# RP2040 register map
Vendor: Raspberry Pi; File version: 2025.06.15
CPU: CM0PLUS r0p1, little endian, 2 interrupt priority bits
Registers are 32-bit, read-write, no defined reset value unless marked. A register's access mark holds for its fields unless they carry their own. Offsets are from the block's base; [hi:lo] are bit positions; {n}, {i} and the like mark numbered series; 'fields as' and 'values as' point back to an identical list.

## CLOCKS
Base 0x40008000
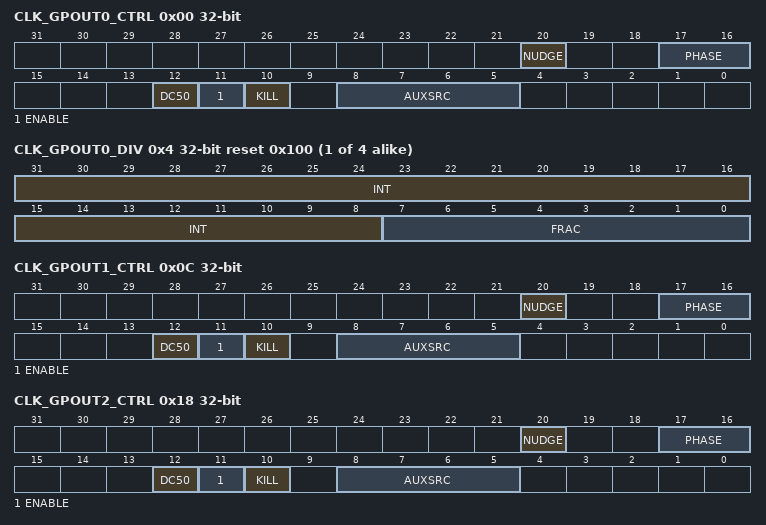
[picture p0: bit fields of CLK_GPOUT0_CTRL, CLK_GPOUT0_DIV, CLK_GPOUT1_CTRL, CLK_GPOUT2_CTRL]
0x00 CLK_GPOUT0_CTRL — Clock control, can be changed on-the-fly (except for auxsrc)
  [20] NUDGE — An edge on this signal shifts the phase of the output by 1 cycle of the input clock This can be done at any time
  [17:16] PHASE — This delays the enable signal by up to 3 cycles of the input clock This must be set before the clock is enabled to have any effect
  [12] DC50 — Enables duty cycle correction for odd divisors
  [11] ENABLE — Starts and stops the clock generator cleanly
  [10] KILL — Asynchronously kills the clock generator
  [8:5] AUXSRC — Selects the auxiliary clock source, will glitch when switching
    0=clksrc_pll_sys (None); 1=clksrc_gpin0 (None); 10=clk_ref (None); 2=clksrc_gpin1 (None); 3=clksrc_pll_usb (None); 4=rosc_clksrc (None); 5=xosc_clksrc (None); 6=clk_sys (None); 7=clk_usb (None); 8=clk_adc (None); 9=clk_rtc (None)
{0x4+0xC*i} CLK_GPOUT{i}_DIV reset 0x100 (reset mask 0x0) (i=0..3) — Clock divisor, can be changed on-the-fly
  [31:8] INT — Integer component of the divisor, 0 -> divide by 2^16
  [7:0] FRAC — Fractional component of the divisor
{0x8+0xC*i} CLK_GPOUT{i}_SELECTED ro reset 0x1 (reset mask 0x0) (i=0..3) — Indicates which SRC is currently selected by the glitchless mux (one-hot). This slice does not have a glitchless mux (only the AUX_SRC field is present, not SRC) so this register is hardwired to 0x1.
0x0C CLK_GPOUT1_CTRL — Clock control, can be changed on-the-fly (except for auxsrc)
  fields as CLK_GPOUT0_CTRL
0x18 CLK_GPOUT2_CTRL — Clock control, can be changed on-the-fly (except for auxsrc)
  [20] NUDGE — An edge on this signal shifts the phase of the output by 1 cycle of the input clock This can be done at any time
  [17:16] PHASE — This delays the enable signal by up to 3 cycles of the input clock This must be set before the clock is enabled to have any effect
  [12] DC50 — Enables duty cycle correction for odd divisors
  [11] ENABLE — Starts and stops the clock generator cleanly
  [10] KILL — Asynchronously kills the clock generator
  [8:5] AUXSRC — Selects the auxiliary clock source, will glitch when switching
    0=clksrc_pll_sys (None); 1=clksrc_gpin0 (None); 10=clk_ref (None); 2=clksrc_gpin1 (None); 3=clksrc_pll_usb (None); 4=rosc_clksrc_ph (None); 5=xosc_clksrc (None); 6=clk_sys (None); 7=clk_usb (None); 8=clk_adc (None); 9=clk_rtc (None)
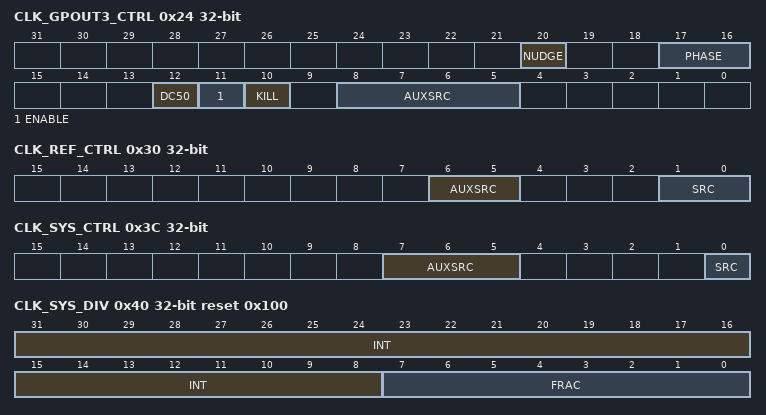
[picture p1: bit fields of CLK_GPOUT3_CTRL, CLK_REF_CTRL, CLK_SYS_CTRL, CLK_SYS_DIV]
0x24 CLK_GPOUT3_CTRL — Clock control, can be changed on-the-fly (except for auxsrc)
  fields as CLK_GPOUT2_CTRL
0x30 CLK_REF_CTRL — Clock control, can be changed on-the-fly (except for auxsrc)
  [6:5] AUXSRC — Selects the auxiliary clock source, will glitch when switching
    0=clksrc_pll_usb (None); 1=clksrc_gpin0 (None); 2=clksrc_gpin1 (None)
  [1:0] SRC — Selects the clock source glitchlessly, can be changed on-the-fly
    0=rosc_clksrc_ph (None); 1=clksrc_clk_ref_aux (None); 2=xosc_clksrc (None)
0x34 CLK_REF_DIV reset 0x100 (reset mask 0x0) — Clock divisor, can be changed on-the-fly
  [9:8] INT — Integer component of the divisor, 0 -> divide by 2^16
0x38 CLK_REF_SELECTED ro reset 0x1 (reset mask 0x0) — Indicates which SRC is currently selected by the glitchless mux (one-hot). The glitchless multiplexer does not switch instantaneously (to avoid glitches), so software should poll this register to wait for the switch to complete. This register contains one decoded bit for each of the clock sources enumerated in the CTRL SRC field. At most one of these bits will be set at any time, indicating that clock is currently present at the output of the glitchless mux. Whilst switching is in progress, this register may briefly show all-0s.
0x3C CLK_SYS_CTRL — Clock control, can be changed on-the-fly (except for auxsrc)
  [7:5] AUXSRC — Selects the auxiliary clock source, will glitch when switching
    0=clksrc_pll_sys (None); 1=clksrc_pll_usb (None); 2=rosc_clksrc (None); 3=xosc_clksrc (None); 4=clksrc_gpin0 (None); 5=clksrc_gpin1 (None)
  [0] SRC — Selects the clock source glitchlessly, can be changed on-the-fly
    0=clk_ref (None); 1=clksrc_clk_sys_aux (None)
0x40 CLK_SYS_DIV reset 0x100 (reset mask 0x0) — Clock divisor, can be changed on-the-fly
  fields as CLK_GPOUT0_DIV
0x44 CLK_SYS_SELECTED ro reset 0x1 (reset mask 0x0) — Indicates which SRC is currently selected by the glitchless mux (one-hot). The glitchless multiplexer does not switch instantaneously (to avoid glitches), so software should poll this register to wait for the switch to complete. This register contains one decoded bit for each of the clock sources enumerated in the CTRL SRC field. At most one of these bits will be set at any time, indicating that clock is currently present at the output of the glitchless mux. Whilst switching is in progress, this register may briefly show all-0s.
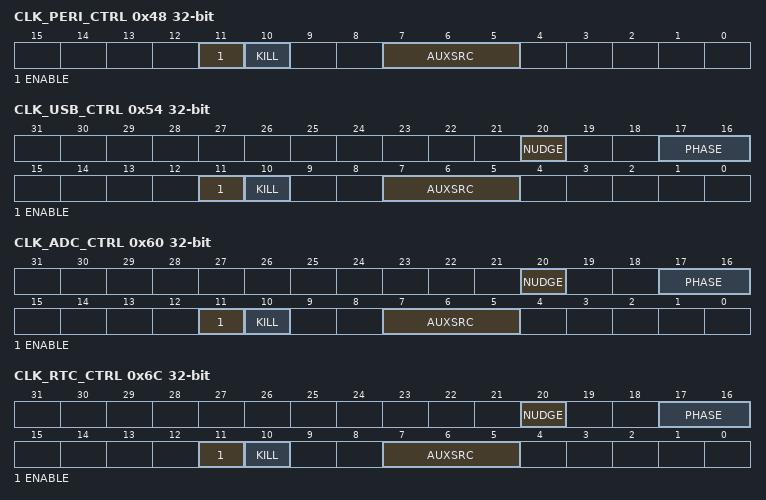
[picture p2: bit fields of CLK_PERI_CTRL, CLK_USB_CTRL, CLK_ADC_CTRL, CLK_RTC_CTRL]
0x48 CLK_PERI_CTRL — Clock control, can be changed on-the-fly (except for auxsrc)
  [11] ENABLE — Starts and stops the clock generator cleanly
  [10] KILL — Asynchronously kills the clock generator
  [7:5] AUXSRC — Selects the auxiliary clock source, will glitch when switching
    0=clk_sys (None); 1=clksrc_pll_sys (None); 2=clksrc_pll_usb (None); 3=rosc_clksrc_ph (None); 4=xosc_clksrc (None); 5=clksrc_gpin0 (None); 6=clksrc_gpin1 (None)
0x50 CLK_PERI_SELECTED ro reset 0x1 (reset mask 0x0) — Indicates which SRC is currently selected by the glitchless mux (one-hot). This slice does not have a glitchless mux (only the AUX_SRC field is present, not SRC) so this register is hardwired to 0x1.
0x54 CLK_USB_CTRL — Clock control, can be changed on-the-fly (except for auxsrc)
  [20] NUDGE — An edge on this signal shifts the phase of the output by 1 cycle of the input clock This can be done at any time
  [17:16] PHASE — This delays the enable signal by up to 3 cycles of the input clock This must be set before the clock is enabled to have any effect
  [11] ENABLE — Starts and stops the clock generator cleanly
  [10] KILL — Asynchronously kills the clock generator
  [7:5] AUXSRC — Selects the auxiliary clock source, will glitch when switching
    0=clksrc_pll_usb (None); 1=clksrc_pll_sys (None); 2=rosc_clksrc_ph (None); 3=xosc_clksrc (None); 4=clksrc_gpin0 (None); 5=clksrc_gpin1 (None)
0x58 CLK_USB_DIV reset 0x100 (reset mask 0x0) — Clock divisor, can be changed on-the-fly
  [9:8] INT — Integer component of the divisor, 0 -> divide by 2^16
0x5C CLK_USB_SELECTED ro reset 0x1 (reset mask 0x0) — Indicates which SRC is currently selected by the glitchless mux (one-hot). This slice does not have a glitchless mux (only the AUX_SRC field is present, not SRC) so this register is hardwired to 0x1.
0x60 CLK_ADC_CTRL — Clock control, can be changed on-the-fly (except for auxsrc)
  fields as CLK_USB_CTRL
0x64 CLK_ADC_DIV reset 0x100 (reset mask 0x0) — Clock divisor, can be changed on-the-fly
  [9:8] INT — Integer component of the divisor, 0 -> divide by 2^16
0x68 CLK_ADC_SELECTED ro reset 0x1 (reset mask 0x0) — Indicates which SRC is currently selected by the glitchless mux (one-hot). This slice does not have a glitchless mux (only the AUX_SRC field is present, not SRC) so this register is hardwired to 0x1.
0x6C CLK_RTC_CTRL — Clock control, can be changed on-the-fly (except for auxsrc)
  fields as CLK_USB_CTRL
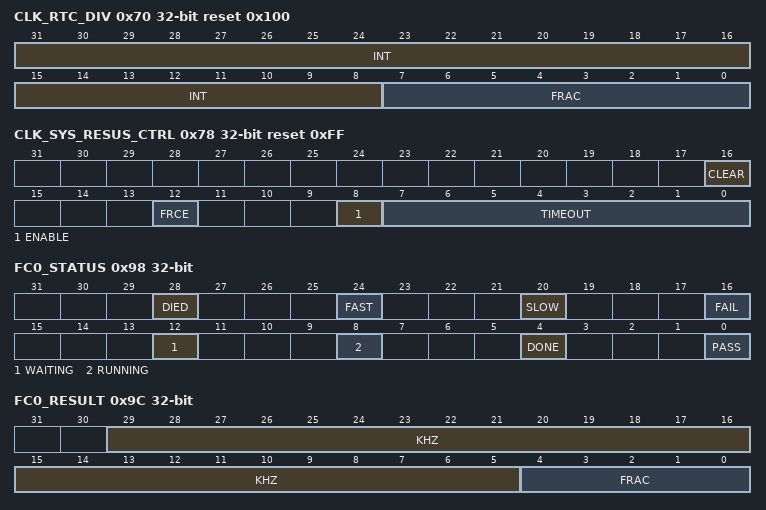
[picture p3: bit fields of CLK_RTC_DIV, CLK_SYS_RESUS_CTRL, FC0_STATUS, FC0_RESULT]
0x70 CLK_RTC_DIV reset 0x100 (reset mask 0x0) — Clock divisor, can be changed on-the-fly
  fields as CLK_GPOUT0_DIV
0x74 CLK_RTC_SELECTED ro reset 0x1 (reset mask 0x0) — Indicates which SRC is currently selected by the glitchless mux (one-hot). This slice does not have a glitchless mux (only the AUX_SRC field is present, not SRC) so this register is hardwired to 0x1.
0x78 CLK_SYS_RESUS_CTRL reset 0xFF (reset mask 0x0)
  [16] CLEAR — For clearing the resus after the fault that triggered it has been corrected
  [12] FRCE — Force a resus, for test purposes only
  [8] ENABLE — Enable resus
  [7:0] TIMEOUT — This is expressed as a number of clk_ref cycles and must be >= 2x clk_ref_freq/min_clk_tst_freq
0x7C CLK_SYS_RESUS_STATUS
  [0] RESUSSED ro — Clock has been resuscitated, correct the error then send ctrl_clear=1
0x80 FC0_REF_KHZ — Reference clock frequency in kHz
  [19:0] FC0_REF_KHZ
0x84 FC0_MIN_KHZ — Minimum pass frequency in kHz. This is optional. Set to 0 if you are not using the pass/fail flags
  [24:0] FC0_MIN_KHZ
0x88 FC0_MAX_KHZ reset 0x1FFFFFF (reset mask 0x0) — Maximum pass frequency in kHz. This is optional. Set to 0x1ffffff if you are not using the pass/fail flags
  [24:0] FC0_MAX_KHZ
0x8C FC0_DELAY reset 0x1 (reset mask 0x0) — Delays the start of frequency counting to allow the mux to settle Delay is measured in multiples of the reference clock period
  [2:0] FC0_DELAY
0x90 FC0_INTERVAL reset 0x8 (reset mask 0x0) — The test interval is 0.98us * 2**interval, but let's call it 1us * 2**interval The default gives a test interval of 250us
  [3:0] FC0_INTERVAL
0x94 FC0_SRC — Clock sent to frequency counter, set to 0 when not required Writing to this register initiates the frequency count
  [7:0] FC0_SRC
    0=NULL (None); 1=pll_sys_clksrc_primary (None); 10=clk_peri (None); 11=clk_usb (None); 12=clk_adc (None); 13=clk_rtc (None); 2=pll_usb_clksrc_primary (None); 3=rosc_clksrc (None); 4=rosc_clksrc_ph (None); 5=xosc_clksrc (None); 6=clksrc_gpin0 (None); 7=clksrc_gpin1 (None); 8=clk_ref (None); 9=clk_sys (None)
0x98 FC0_STATUS — Frequency counter status
  [28] DIED ro — Test clock stopped during test
  [24] FAST ro — Test clock faster than expected, only valid when status_done=1
  [20] SLOW ro — Test clock slower than expected, only valid when status_done=1
  [16] FAIL ro — Test failed
  [12] WAITING ro — Waiting for test clock to start
  [8] RUNNING ro — Test running
  [4] DONE ro — Test complete
  [0] PASS ro — Test passed
0x9C FC0_RESULT — Result of frequency measurement, only valid when status_done=1
  [29:5] KHZ ro, [4:0] FRAC ro
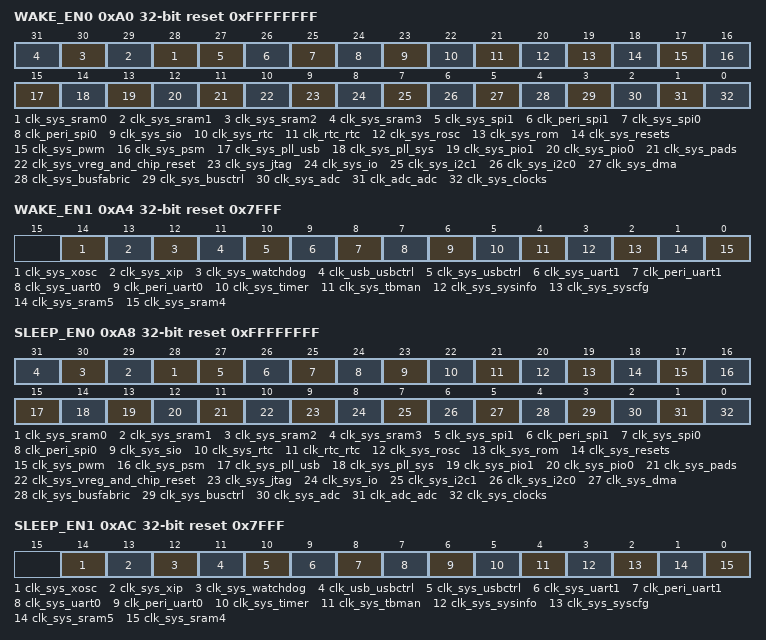
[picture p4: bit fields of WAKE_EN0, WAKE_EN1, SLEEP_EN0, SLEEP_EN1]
0xA0 WAKE_EN0 reset 0xFFFFFFFF (reset mask 0x0) — enable clock in wake mode
  [n+28] clk_sys_sram{n} (n=0..3), [27] clk_sys_spi1, [26] clk_peri_spi1, [25] clk_sys_spi0, [24] clk_peri_spi0, [23] clk_sys_sio, [22] clk_sys_rtc, [21] clk_rtc_rtc, [20] clk_sys_rosc, [19] clk_sys_rom, [18] clk_sys_resets, [17] clk_sys_pwm, [16] clk_sys_psm, [15] clk_sys_pll_usb, [14] clk_sys_pll_sys, [13] clk_sys_pio1, [12] clk_sys_pio0, [11] clk_sys_pads, [10] clk_sys_vreg_and_chip_reset, [9] clk_sys_jtag, [8] clk_sys_io, [7] clk_sys_i2c1, [6] clk_sys_i2c0, [5] clk_sys_dma, [4] clk_sys_busfabric, [3] clk_sys_busctrl, [2] clk_sys_adc, [1] clk_adc_adc, [0] clk_sys_clocks
0xA4 WAKE_EN1 reset 0x7FFF (reset mask 0x0) — enable clock in wake mode
  [14] clk_sys_xosc, [13] clk_sys_xip, [12] clk_sys_watchdog, [11] clk_usb_usbctrl, [10] clk_sys_usbctrl, [9] clk_sys_uart1, [8] clk_peri_uart1, [7] clk_sys_uart0, [6] clk_peri_uart0, [5] clk_sys_timer, [4] clk_sys_tbman, [3] clk_sys_sysinfo, [2] clk_sys_syscfg, [1] clk_sys_sram5, [0] clk_sys_sram4
0xA8 SLEEP_EN0 reset 0xFFFFFFFF (reset mask 0x0) — enable clock in sleep mode
  fields as WAKE_EN0
0xAC SLEEP_EN1 reset 0x7FFF (reset mask 0x0) — enable clock in sleep mode
  fields as WAKE_EN1
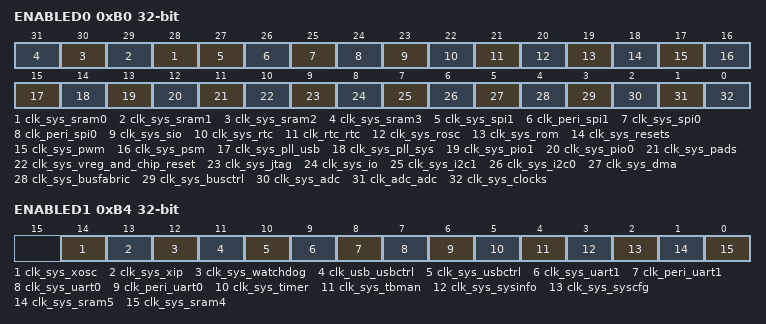
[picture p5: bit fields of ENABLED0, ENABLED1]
0xB0 ENABLED0 — indicates the state of the clock enable
  [n+28] clk_sys_sram{n} ro (n=0..3), [27] clk_sys_spi1 ro, [26] clk_peri_spi1 ro, [25] clk_sys_spi0 ro, [24] clk_peri_spi0 ro, [23] clk_sys_sio ro, [22] clk_sys_rtc ro, [21] clk_rtc_rtc ro, [20] clk_sys_rosc ro, [19] clk_sys_rom ro, [18] clk_sys_resets ro, [17] clk_sys_pwm ro, [16] clk_sys_psm ro, [15] clk_sys_pll_usb ro, [14] clk_sys_pll_sys ro, [13] clk_sys_pio1 ro, [12] clk_sys_pio0 ro, [11] clk_sys_pads ro, [10] clk_sys_vreg_and_chip_reset ro, [9] clk_sys_jtag ro, [8] clk_sys_io ro, [7] clk_sys_i2c1 ro, [6] clk_sys_i2c0 ro, [5] clk_sys_dma ro, [4] clk_sys_busfabric ro, [3] clk_sys_busctrl ro, [2] clk_sys_adc ro, [1] clk_adc_adc ro, [0] clk_sys_clocks ro
0xB4 ENABLED1 — indicates the state of the clock enable
  [14] clk_sys_xosc ro, [13] clk_sys_xip ro, [12] clk_sys_watchdog ro, [11] clk_usb_usbctrl ro, [10] clk_sys_usbctrl ro, [9] clk_sys_uart1 ro, [8] clk_peri_uart1 ro, [7] clk_sys_uart0 ro, [6] clk_peri_uart0 ro, [5] clk_sys_timer ro, [4] clk_sys_tbman ro, [3] clk_sys_sysinfo ro, [2] clk_sys_syscfg ro, [1] clk_sys_sram5 ro, [0] clk_sys_sram4 ro
0xB8 INTR — Raw Interrupts
  [0] CLK_SYS_RESUS ro
0xBC INTE — Interrupt Enable
  [0] CLK_SYS_RESUS
0xC0 INTF — Interrupt Force
  [0] CLK_SYS_RESUS
0xC4 INTS — Interrupt status after masking & forcing
  [0] CLK_SYS_RESUS ro
